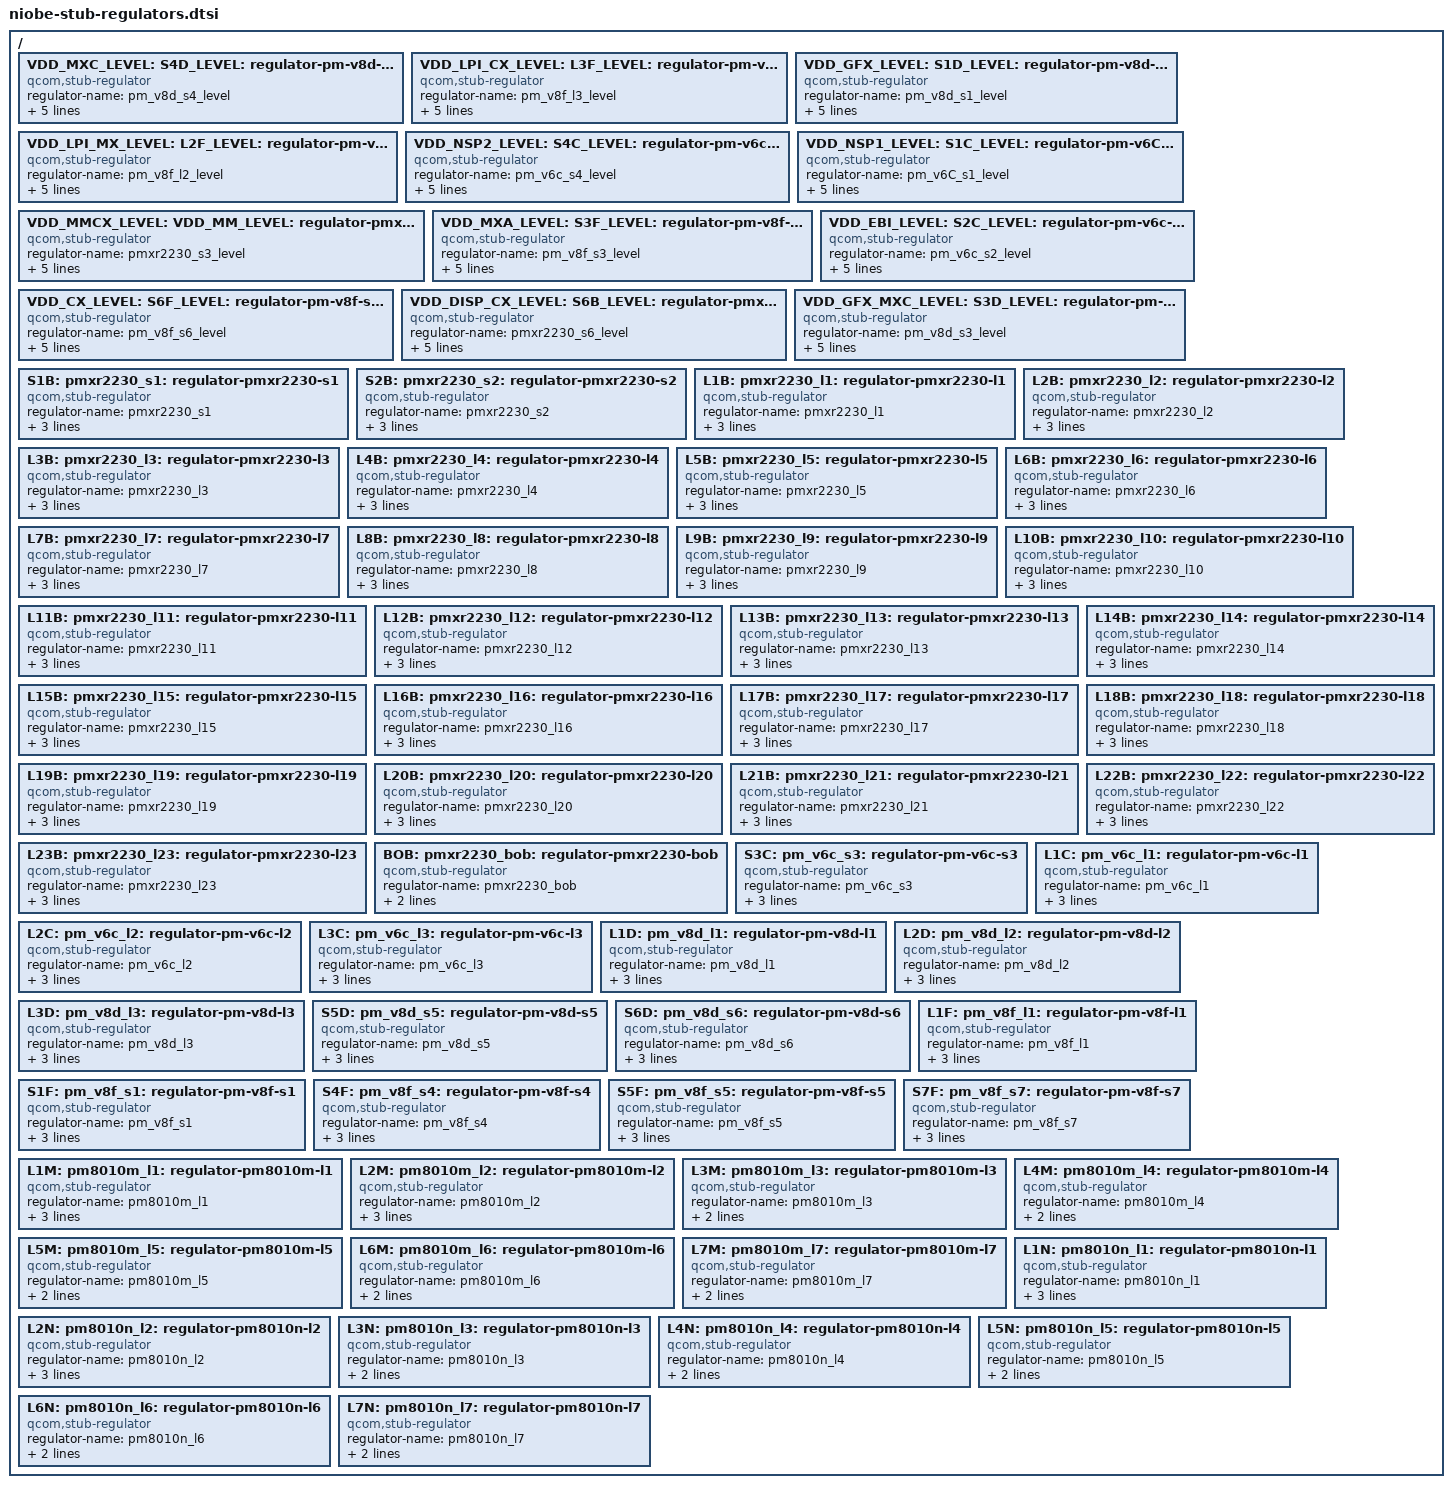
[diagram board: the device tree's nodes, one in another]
#include <dt-bindings/regulator/qcom,rpmh-regulator-levels.h>

/ {
	VDD_MXC_LEVEL: S4D_LEVEL:
	VDD_MM_MXC_VOTER_LEVEL: VDD_GFX_MXC_VOTER_LEVEL:
	pm_v8d_s4_level: regulator-pm-v8d-s4-level {
		compatible = "qcom,stub-regulator";
		regulator-name = "pm_v8d_s4_level";
		regulator-min-microvolt = <RPMH_REGULATOR_LEVEL_RETENTION>;
		regulator-max-microvolt = <RPMH_REGULATOR_LEVEL_MAX>;
		qcom,hpm-min-load = <10000>;
	};

	VDD_LPI_CX_LEVEL: L3F_LEVEL:
	pm_v8f_l3_level: regulator-pm-v8f-l3-level {
		compatible = "qcom,stub-regulator";
		regulator-name = "pm_v8f_l3_level";
		regulator-min-microvolt = <RPMH_REGULATOR_LEVEL_RETENTION>;
		regulator-max-microvolt = <RPMH_REGULATOR_LEVEL_MAX>;
		qcom,hpm-min-load = <10000>;
	};

	VDD_GFX_LEVEL: S1D_LEVEL:
	pm_v8d_s1_level: regulator-pm-v8d-s1-level {
		compatible = "qcom,stub-regulator";
		regulator-name = "pm_v8d_s1_level";
		regulator-min-microvolt = <RPMH_REGULATOR_LEVEL_RETENTION>;
		regulator-max-microvolt = <RPMH_REGULATOR_LEVEL_MAX>;
		qcom,hpm-min-load = <10000>;
	};

	VDD_LPI_MX_LEVEL: L2F_LEVEL:
	pm_v8f_l2_level: regulator-pm-v8f-l2-level {
		compatible = "qcom,stub-regulator";
		regulator-name = "pm_v8f_l2_level";
		regulator-min-microvolt = <RPMH_REGULATOR_LEVEL_RETENTION>;
		regulator-max-microvolt = <RPMH_REGULATOR_LEVEL_MAX>;
		qcom,hpm-min-load = <10000>;
	};

	VDD_NSP2_LEVEL: S4C_LEVEL:
	pm_v6c_s4_level: regulator-pm-v6c-s4-level {
		compatible = "qcom,stub-regulator";
		regulator-name = "pm_v6c_s4_level";
		regulator-min-microvolt = <RPMH_REGULATOR_LEVEL_RETENTION>;
		regulator-max-microvolt = <RPMH_REGULATOR_LEVEL_MAX>;
		qcom,hpm-min-load = <10000>;
	};

	VDD_NSP1_LEVEL: S1C_LEVEL:
	pm_v6C_s1_level: regulator-pm-v6C-s1-level {
		compatible = "qcom,stub-regulator";
		regulator-name = "pm_v6C_s1_level";
		regulator-min-microvolt = <RPMH_REGULATOR_LEVEL_RETENTION>;
		regulator-max-microvolt = <RPMH_REGULATOR_LEVEL_MAX>;
		qcom,hpm-min-load = <10000>;
	};

	VDD_MMCX_LEVEL: VDD_MM_LEVEL: S3B_LEVEL:
	pmxr2230_s3_level: regulator-pmxr2230-s3-level {
		compatible = "qcom,stub-regulator";
		regulator-name = "pmxr2230_s3_level";
		regulator-min-microvolt = <RPMH_REGULATOR_LEVEL_RETENTION>;
		regulator-max-microvolt = <RPMH_REGULATOR_LEVEL_MAX>;
		qcom,hpm-min-load = <10000>;
	};

	VDD_MXA_LEVEL: S3F_LEVEL:
	pm_v8f_s3_level: regulator-pm-v8f-s3-level {
		compatible = "qcom,stub-regulator";
		regulator-name = "pm_v8f_s3_level";
		regulator-min-microvolt = <RPMH_REGULATOR_LEVEL_RETENTION>;
		regulator-max-microvolt = <RPMH_REGULATOR_LEVEL_MAX>;
		qcom,hpm-min-load = <10000>;
	};

	VDD_EBI_LEVEL: S2C_LEVEL:
	pm_v6c_s2_level: regulator-pm-v6c-s2-level {
		compatible = "qcom,stub-regulator";
		regulator-name = "pm_v6c_s2_level";
		regulator-min-microvolt = <RPMH_REGULATOR_LEVEL_RETENTION>;
		regulator-max-microvolt = <RPMH_REGULATOR_LEVEL_MAX>;
		qcom,hpm-min-load = <10000>;
	};

	VDD_CX_LEVEL: S6F_LEVEL:
	pm_v8f_s6_level: regulator-pm-v8f-s6-level {
		compatible = "qcom,stub-regulator";
		regulator-name = "pm_v8f_s6_level";
		regulator-min-microvolt = <RPMH_REGULATOR_LEVEL_RETENTION>;
		regulator-max-microvolt = <RPMH_REGULATOR_LEVEL_MAX>;
		qcom,hpm-min-load = <10000>;
	};

	VDD_DISP_CX_LEVEL: S6B_LEVEL:
	pmxr2230_s6_level: regulator-pmxr2230-s6-level {
		compatible = "qcom,stub-regulator";
		regulator-name = "pmxr2230_s6_level";
		regulator-min-microvolt = <RPMH_REGULATOR_LEVEL_RETENTION>;
		regulator-max-microvolt = <RPMH_REGULATOR_LEVEL_MAX>;
		qcom,hpm-min-load = <10000>;
	};

	VDD_GFX_MXC_LEVEL: S3D_LEVEL:
	VDD_GFX_MXC_GFX_VOTER_LEVEL: VDD_GFX_GFX_MXC_VOTER_LEVEL:
	pm_v8d_s3_level: regulator-pm-v8d-s3-level {
		compatible = "qcom,stub-regulator";
		regulator-name = "pm_v8d_s3_level";
		regulator-min-microvolt = <RPMH_REGULATOR_LEVEL_RETENTION>;
		regulator-max-microvolt = <RPMH_REGULATOR_LEVEL_MAX>;
		qcom,hpm-min-load = <10000>;
	};

	S1B: pmxr2230_s1: regulator-pmxr2230-s1 {
		compatible = "qcom,stub-regulator";
		regulator-name = "pmxr2230_s1";
		regulator-min-microvolt = <1250000>;
		regulator-max-microvolt = <2100000>;
		qcom,hpm-min-load = <10000>;
	};

	S2B: pmxr2230_s2: regulator-pmxr2230-s2 {
		compatible = "qcom,stub-regulator";
		regulator-name = "pmxr2230_s2";
		regulator-min-microvolt = <975000>;
		regulator-max-microvolt = <2100000>;
		qcom,hpm-min-load = <10000>;
	};

	L1B: pmxr2230_l1: regulator-pmxr2230-l1 {
		compatible = "qcom,stub-regulator";
		regulator-name = "pmxr2230_l1";
		regulator-min-microvolt = <830000>;
		regulator-max-microvolt = <912000>;
		com,hpm-min-load = <10000>;
	};

	L2B: pmxr2230_l2: regulator-pmxr2230-l2 {
		compatible = "qcom,stub-regulator";
		regulator-name = "pmxr2230_l2";
		regulator-min-microvolt = <1170000>;
		regulator-max-microvolt = <1370000>;
		qcom,hpm-min-load = <10000>;
	};

	L3B: pmxr2230_l3: regulator-pmxr2230-l3 {
		compatible = "qcom,stub-regulator";
		regulator-name = "pmxr2230_l3";
		regulator-min-microvolt = <1000000>;
		regulator-max-microvolt = <1980000>;
		qcom,hpm-min-load = <10000>;
	};

	L4B: pmxr2230_l4: regulator-pmxr2230-l4 {
		compatible = "qcom,stub-regulator";
		regulator-name = "pmxr2230_l4";
		regulator-min-microvolt = <1700000>;
		regulator-max-microvolt = <1900000>;
		qcom,hpm-min-load = <10000>;
	};

	L5B: pmxr2230_l5: regulator-pmxr2230-l5 {
		compatible = "qcom,stub-regulator";
		regulator-name = "pmxr2230_l5";
		regulator-min-microvolt = <320000>;
		regulator-max-microvolt = <2000000>;
		qcom,hpm-min-load = <10000>;
	};

	L6B: pmxr2230_l6: regulator-pmxr2230-l6 {
		compatible = "qcom,stub-regulator";
		regulator-name = "pmxr2230_l6";
		regulator-min-microvolt = <1080000>;
		regulator-max-microvolt = <2000000>;
		qcom,hpm-min-load = <10000>;
	};

	L7B: pmxr2230_l7: regulator-pmxr2230-l7 {
		compatible = "qcom,stub-regulator";
		regulator-name = "pmxr2230_l7";
		regulator-min-microvolt = <1620000>;
		regulator-max-microvolt = <2000000>;
		qcom,hpm-min-load = <10000>;
	};

	L8B: pmxr2230_l8: regulator-pmxr2230-l8 {
		compatible = "qcom,stub-regulator";
		regulator-name = "pmxr2230_l8";
		regulator-min-microvolt = <830000>;
		regulator-max-microvolt = <920000>;
		qcom,hpm-min-load = <10000>;
	};

	L9B: pmxr2230_l9: regulator-pmxr2230-l9 {
		compatible = "qcom,stub-regulator";
		regulator-name = "pmxr2230_l9";
		regulator-min-microvolt = <830000>;
		regulator-max-microvolt = <920000>;
		qcom,hpm-min-load = <10000>;
	};

	L10B: pmxr2230_l10: regulator-pmxr2230-l10 {
		compatible = "qcom,stub-regulator";
		regulator-name = "pmxr2230_l10";
		regulator-min-microvolt = <720000>;
		regulator-max-microvolt = <950000>;
		qcom,hpm-min-load = <10000>;
	};

	L11B: pmxr2230_l11: regulator-pmxr2230-l11 {
		compatible = "qcom,stub-regulator";
		regulator-name = "pmxr2230_l11";
		regulator-min-microvolt = <1650000>;
		regulator-max-microvolt = <2000000>;
		qcom,hpm-min-load = <10000>;
	};

	L12B: pmxr2230_l12: regulator-pmxr2230-l12 {
		compatible = "qcom,stub-regulator";
		regulator-name = "pmxr2230_l12";
		regulator-min-microvolt = <2700000>;
		regulator-max-microvolt = <3300000>;
		qcom,hpm-min-load = <10000>;
	};

	L13B: pmxr2230_l13: regulator-pmxr2230-l13 {
		compatible = "qcom,stub-regulator";
		regulator-name = "pmxr2230_l13";
		regulator-min-microvolt = <2400000>;
		regulator-max-microvolt = <3300000>;
		qcom,hpm-min-load = <10000>;
	};

	L14B: pmxr2230_l14: regulator-pmxr2230-l14 {
		compatible = "qcom,stub-regulator";
		regulator-name = "pmxr2230_l14";
		regulator-min-microvolt = <2800000>;
		regulator-max-microvolt = <3544000>;
		qcom,hpm-min-load = <10000>;
	};

	L15B: pmxr2230_l15: regulator-pmxr2230-l15 {
		compatible = "qcom,stub-regulator";
		regulator-name = "pmxr2230_l15";
		regulator-min-microvolt = <2700000>;
		regulator-max-microvolt = <3300000>;
		qcom,hpm-min-load = <10000>;
	};

	L16B: pmxr2230_l16: regulator-pmxr2230-l16 {
		compatible = "qcom,stub-regulator";
		regulator-name = "pmxr2230_l16";
		regulator-min-microvolt = <1504000>;
		regulator-max-microvolt = <3544000>;
		qcom,hpm-min-load = <10000>;
	};

	L17B: pmxr2230_l17: regulator-pmxr2230-l17 {
		compatible = "qcom,stub-regulator";
		regulator-name = "pmxr2230_l17";
		regulator-min-microvolt = <1504000>;
		regulator-max-microvolt = <3544000>;
		qcom,hpm-min-load = <10000>;
	};

	L18B: pmxr2230_l18: regulator-pmxr2230-l18 {
		compatible = "qcom,stub-regulator";
		regulator-name = "pmxr2230_l18";
		regulator-min-microvolt = <1504000>;
		regulator-max-microvolt = <3544000>;
		qcom,hpm-min-load = <10000>;
	};

	L19B: pmxr2230_l19: regulator-pmxr2230-l19 {
		compatible = "qcom,stub-regulator";
		regulator-name = "pmxr2230_l19";
		regulator-min-microvolt = <1650000>;
		regulator-max-microvolt = <3544000>;
		qcom,hpm-min-load = <10000>;
	};

	L20B: pmxr2230_l20: regulator-pmxr2230-l20 {
		compatible = "qcom,stub-regulator";
		regulator-name = "pmxr2230_l20";
		regulator-min-microvolt = <1504000>;
		regulator-max-microvolt = <3544000>;
		qcom,hpm-min-load = <10000>;
	};

	L21B: pmxr2230_l21: regulator-pmxr2230-l21 {
		compatible = "qcom,stub-regulator";
		regulator-name = "pmxr2230_l21";
		regulator-min-microvolt = <2600000>;
		regulator-max-microvolt = <3000000>;
		qcom,hpm-min-load = <10000>;
	};

	L22B: pmxr2230_l22: regulator-pmxr2230-l22 {
		compatible = "qcom,stub-regulator";
		regulator-name = "pmxr2230_l22";
		regulator-min-microvolt = <2600000>;
		regulator-max-microvolt = <3000000>;
		qcom,hpm-min-load = <10000>;
	};

	L23B: pmxr2230_l23: regulator-pmxr2230-l23 {
		compatible = "qcom,stub-regulator";
		regulator-name = "pmxr2230_l23";
		regulator-min-microvolt = <2700000>;
		regulator-max-microvolt = <2900000>;
		qcom,hpm-min-load = <10000>;
	};

	BOB: pmxr2230_bob: regulator-pmxr2230-bob {
		compatible = "qcom,stub-regulator";
		regulator-name = "pmxr2230_bob";
		regulator-min-microvolt = <2200000>;
		regulator-max-microvolt = <4500000>;
	};

	S3C: pm_v6c_s3: regulator-pm-v6c-s3 {
		compatible = "qcom,stub-regulator";
		regulator-name = "pm_v6c_s3";
		regulator-min-microvolt = <300000>;
		regulator-max-microvolt = <570000>;
		qcom,hpm-min-load = <10000>;
	};

	L1C: pm_v6c_l1: regulator-pm-v6c-l1 {
		compatible = "qcom,stub-regulator";
		regulator-name = "pm_v6c_l1";
		regulator-min-microvolt = <1200000>;
		regulator-max-microvolt = <1200000>;
		qcom,hpm-min-load = <10000>;
	};

	L2C: pm_v6c_l2: regulator-pm-v6c-l2 {
		compatible = "qcom,stub-regulator";
		regulator-name = "pm_v6c_l2";
		regulator-min-microvolt = <870000>;
		regulator-max-microvolt = <970000>;
		qcom,hpm-min-load = <10000>;
	};

	L3C: pm_v6c_l3: regulator-pm-v6c-l3 {
		compatible = "qcom,stub-regulator";
		regulator-name = "pm_v6c_l3";
		regulator-min-microvolt = <866000>;
		regulator-max-microvolt = <958000>;
		qcom,hpm-min-load = <30000>;
	};

	L1D: pm_v8d_l1: regulator-pm-v8d-l1 {
		compatible = "qcom,stub-regulator";
		regulator-name = "pm_v8d_l1";
		regulator-min-microvolt = <1080000>;
		regulator-max-microvolt = <1320000>;
		qcom,hpm-min-load = <30000>;
	};

	L2D: pm_v8d_l2: regulator-pm-v8d-l2 {
		compatible = "qcom,stub-regulator";
		regulator-name = "pm_v8d_l2";
		regulator-min-microvolt = <830000>;
		regulator-max-microvolt = <920000>;
		qcom,hpm-min-load = <30000>;
	};

	L3D: pm_v8d_l3: regulator-pm-v8d-l3 {
		compatible = "qcom,stub-regulator";
		regulator-name = "pm_v8d_l3";
		regulator-min-microvolt = <830000>;
		regulator-max-microvolt = <920000>;
		qcom,hpm-min-load = <30000>;
	};

	S5D: pm_v8d_s5: regulator-pm-v8d-s5 {
		compatible = "qcom,stub-regulator";
		regulator-name = "pm_v8d_s5";
		regulator-min-microvolt = <700000>;
		regulator-max-microvolt = <2100000>;
		qcom,hpm-min-load = <10000>;
	};

	S6D: pm_v8d_s6: regulator-pm-v8d-s6 {
		compatible = "qcom,stub-regulator";
		regulator-name = "pm_v8d_s6";
		regulator-min-microvolt = <700000>;
		regulator-max-microvolt = <2100000>;
		qcom,hpm-min-load = <10000>;
	};

	L1F: pm_v8f_l1: regulator-pm-v8f-l1 {
		compatible = "qcom,stub-regulator";
		regulator-name = "pm_v8f_l1";
		regulator-min-microvolt = <825000>;
		regulator-max-microvolt = <925000>;
		qcom,hpm-min-load = <30000>;
	};

	S1F: pm_v8f_s1: regulator-pm-v8f-s1 {
		compatible = "qcom,stub-regulator";
		regulator-name = "pm_v8f_s1";
		regulator-min-microvolt = <572000>;
		regulator-max-microvolt = <988000>;
		qcom,hpm-min-load = <10000>;
	};

	S4F: pm_v8f_s4: regulator-pm-v8f-s4 {
		compatible = "qcom,stub-regulator";
		regulator-name = "pm_v8f_s4";
		regulator-min-microvolt = <1010000>;
		regulator-max-microvolt = <1170000>;
		qcom,hpm-min-load = <10000>;
	};

	S5F: pm_v8f_s5: regulator-pm-v8f-s5 {
		compatible = "qcom,stub-regulator";
		regulator-name = "pm_v8f_s5";
		regulator-min-microvolt = <870000>;
		regulator-max-microvolt = <970000>;
		qcom,hpm-min-load = <10000>;
	};

	S7F: pm_v8f_s7: regulator-pm-v8f-s7 {
		compatible = "qcom,stub-regulator";
		regulator-name = "pm_v8f_s7";
		regulator-min-microvolt = <572000>;
		regulator-max-microvolt = <988000>;
		qcom,hpm-min-load = <10000>;
	};

	L1M: pm8010m_l1: regulator-pm8010m-l1 {
		compatible = "qcom,stub-regulator";
		regulator-name = "pm8010m_l1";
		regulator-min-microvolt = <1140000>;
		regulator-max-microvolt = <1260000>;
		qcom,hpm-min-load = <30000>;
	};

	L2M: pm8010m_l2: regulator-pm8010m-l2 {
		compatible = "qcom,stub-regulator";
		regulator-name = "pm8010m_l2";
		regulator-min-microvolt = <1050000>;
		regulator-max-microvolt = <1180000>;
		qcom,hpm-min-load = <30000>;
	};

	L3M: pm8010m_l3: regulator-pm8010m-l3 {
		compatible = "qcom,stub-regulator";
		regulator-name = "pm8010m_l3";
		regulator-min-microvolt = <2700000>;
		regulator-max-microvolt = <3000000>;
	};

	L4M: pm8010m_l4: regulator-pm8010m-l4 {
		compatible = "qcom,stub-regulator";
		regulator-name = "pm8010m_l4";
		regulator-min-microvolt = <2700000>;
		regulator-max-microvolt = <3000000>;
	};

	L5M: pm8010m_l5: regulator-pm8010m-l5 {
		compatible = "qcom,stub-regulator";
		regulator-name = "pm8010m_l5";
		regulator-min-microvolt = <2700000>;
		regulator-max-microvolt = <2900000>;
	};

	L6M: pm8010m_l6: regulator-pm8010m-l6 {
		compatible = "qcom,stub-regulator";
		regulator-name = "pm8010m_l6";
		regulator-min-microvolt = <2700000>;
		regulator-max-microvolt = <2900000>;
	};

	L7M: pm8010m_l7: regulator-pm8010m-l7 {
		compatible = "qcom,stub-regulator";
		regulator-name = "pm8010m_l7";
		regulator-min-microvolt = <2700000>;
		regulator-max-microvolt = <3000000>;
	};

	L1N: pm8010n_l1: regulator-pm8010n-l1 {
		compatible = "qcom,stub-regulator";
		regulator-name = "pm8010n_l1";
		regulator-min-microvolt = <1140000>;
		regulator-max-microvolt = <1260000>;
		qcom,hpm-min-load = <30000>;
	};

	L2N: pm8010n_l2: regulator-pm8010n-l2 {
		compatible = "qcom,stub-regulator";
		regulator-name = "pm8010n_l2";
		regulator-min-microvolt = <950000>;
		regulator-max-microvolt = <1150000>;
		qcom,hpm-min-load = <30000>;
	};

	L3N: pm8010n_l3: regulator-pm8010n-l3 {
		compatible = "qcom,stub-regulator";
		regulator-name = "pm8010n_l3";
		regulator-min-microvolt = <2600000>;
		regulator-max-microvolt = <3000000>;
	};

	L4N: pm8010n_l4: regulator-pm8010n-l4 {
		compatible = "qcom,stub-regulator";
		regulator-name = "pm8010n_l4";
		regulator-min-microvolt = <2600000>;
		regulator-max-microvolt = <3000000>;
	};

	L5N: pm8010n_l5: regulator-pm8010n-l5 {
		compatible = "qcom,stub-regulator";
		regulator-name = "pm8010n_l5";
		regulator-min-microvolt = <2700000>;
		regulator-max-microvolt = <2900000>;
	};

	L6N: pm8010n_l6: regulator-pm8010n-l6 {
		compatible = "qcom,stub-regulator";
		regulator-name = "pm8010n_l6";
		regulator-min-microvolt = <2700000>;
		regulator-max-microvolt = <2900000>;
	};

	L7N: pm8010n_l7: regulator-pm8010n-l7 {
		compatible = "qcom,stub-regulator";
		regulator-name = "pm8010n_l7";
		regulator-min-microvolt = <2700000>;
		regulator-max-microvolt = <3000000>;
	};
};
